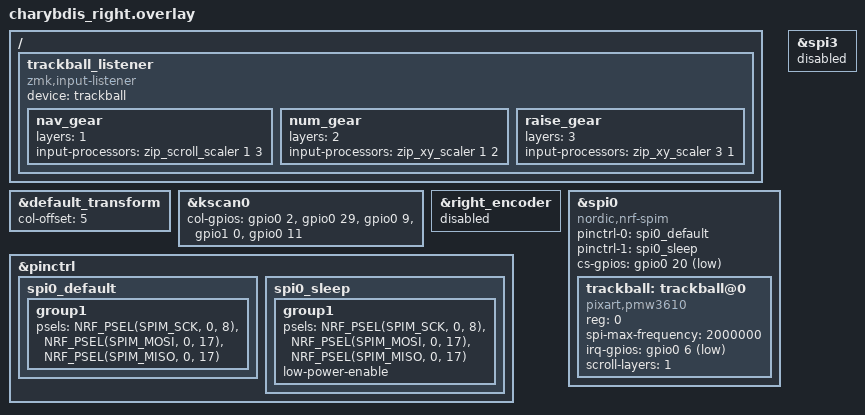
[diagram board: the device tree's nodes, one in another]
/*
 * Copyright (c) 2020 ZMK Contributors
 *
 * SPDX-License-Identifier: MIT
 */
 
#include "charybdis.dtsi"
#include <input/processors.dtsi>

&default_transform {
    col-offset = <5>;
}; 

&kscan0 {
	col-gpios
		= <&gpio0 2 (GPIO_ACTIVE_HIGH | GPIO_PULL_DOWN)>
		, <&gpio0 29 (GPIO_ACTIVE_HIGH | GPIO_PULL_DOWN)>
		, <&gpio0 9 (GPIO_ACTIVE_HIGH | GPIO_PULL_DOWN)>
		, <&gpio1 0  (GPIO_ACTIVE_HIGH | GPIO_PULL_DOWN)>
		, <&gpio0 11 (GPIO_ACTIVE_HIGH | GPIO_PULL_DOWN)>
		
		;
};
&right_encoder {
    status = "disabled";
};

// trackball bus
&pinctrl {
    spi0_default: spi0_default {
        group1 {
            psels = <NRF_PSEL(SPIM_SCK, 0, 8)>,
                <NRF_PSEL(SPIM_MOSI, 0, 17)>,
                <NRF_PSEL(SPIM_MISO, 0, 17)>;
        };
    };

    spi0_sleep: spi0_sleep {
        group1 {
            psels = <NRF_PSEL(SPIM_SCK, 0, 8)>,
                <NRF_PSEL(SPIM_MOSI, 0, 17)>,
                <NRF_PSEL(SPIM_MISO, 0, 17)>;
            low-power-enable;
        };
    };
};

&spi0 {
    status = "okay";
    compatible = "nordic,nrf-spim";
    pinctrl-0 = <&spi0_default>;
    pinctrl-1 = <&spi0_sleep>;
    pinctrl-names = "default", "sleep";
    cs-gpios = <&gpio0 20 GPIO_ACTIVE_LOW>;

    trackball: trackball@0 {
        status = "okay";
        compatible = "pixart,pmw3610";
        reg = <0>;
        spi-max-frequency = <2000000>;
        irq-gpios = <&gpio0 6 (GPIO_ACTIVE_LOW | GPIO_PULL_UP)>;
        scroll-layers = <1>;
        //snipe-layers = <2>;
      // automouse-layer = <3>;
    };
};


// RGB bus - no underglow physically installed on this board, kept disabled
&spi3 {
    status = "disabled";
};



/ {
    trackball_listener: trackball_listener {
        compatible = "zmk,input-listener";
        device = <&trackball>;
    };
};

/*
 * Gearbox: mirrors Temper's own documented NAV/NUM/RSE speed ratios
 * (1/3, 1/2, 3x) onto the real trackball. Right-shield-only, since the
 * shared config/charybdis.keymap compiles for both halves and the left
 * build has no &trackball_listener to reference.
 */
&trackball_listener {
    nav_gear   { layers = <1>; input-processors = <&zip_scroll_scaler 1 3>; };
    num_gear   { layers = <2>; input-processors = <&zip_xy_scaler 1 2>; };
    raise_gear { layers = <3>; input-processors = <&zip_xy_scaler 3 1>; };
};


